# TC37XPD register map
Vendor: Infineon; Series: ATVMC; File version: 100
CPU: other r0p0, little endian, MPU, FPU, vendor SysTick, 4 interrupt priority bits
Registers are 32-bit, read-write, reset 0x0 unless marked. A register's access mark holds for its fields unless they carry their own. Offsets are from the block's base; [hi:lo] are bit positions; {n}, {i} and the like mark numbered series.

## QSPI0 — QSPI
Base 0xF0001C00
Same registers: QSPI1 0xF0001D00, QSPI2 0xF0001E00, QSPI3 0xF0001F00, QSPI4 0xF0002000
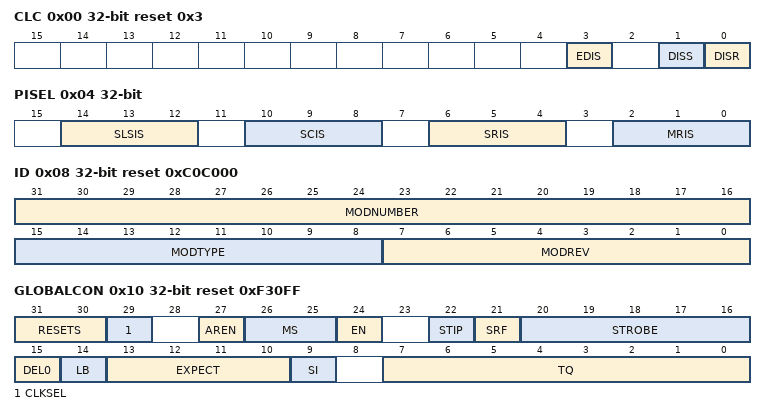
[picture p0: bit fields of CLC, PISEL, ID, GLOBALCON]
0x00 CLC access per field reset 0x3 — Clock Control Register resetvalue={Application Reset:0x3}
  [3] EDIS rw — Sleep Mode Enable Control EDIS. Used to enable the module 8217 s sleep mode.
  [1] DISS ro — Module Disable Status Bit DISS. Bit indicates the current status of the module.
  [0] DISR rw — Module Disable Request Bit DISR. Used for enable disable control of the module.
0x04 PISEL — Port Input Select Register resetvalue={Application Reset:0x0}
  [14:12] SLSIS — Slave Mode Slave Select Input Selection. The SLSIS must be programmed properly before the slave mode is set with GLOBALCON.MODE and the module is set to RUN mode. The following signal sources are available in this product if supported by the package
  [10:8] SCIS — Slave Mode Clock Input Select. SCIS selects one out of eight module kernel SCLK input lines that is used as clock input line in slave mode. Note that not all inputs are used in every device of the family. Selecting an unused input returns a continuous low value. The following signal sources are available in this product if supported by the package
  [6:4] SRIS — Slave Mode Receive Input Select. SRIS selects one out of eight MTSR receive input lines used in Slave Mode. Note that not all inputs are used in every device of the family. Selecting an unused input returns a continuous low value. The following signal sources are available in this product if supported by the package
  [2:0] MRIS — Master Mode Receive Input Select. MRIS selects one out of eight MRST receive input lines used in Master Mode. Note that not all inputs are used in every device of the family. Selecting an unused input returns a continuous low value. The following signal sources are available in this product if supported by the package
0x08 ID ro reset 0xC0C000 (reset mask 0xFFFFFF00) — Module Identification Register resetvalue={Application Reset:0x0C0C000}
  [31:16] MODNUMBER — Module Number Value MODNUMBER. This bit field together with MODTYPE uniquely identifies a module.
  [15:8] MODTYPE — Module Type MODTYPE. This bit field is C0 H . It defines a 32 bit module.
  [7:0] MODREV — Module Revision Number MODREV. MODREV defines the module revision number. The value of a module revision starts with 01 H first revision .
0x10 GLOBALCON access per field reset 0xF30FF — Global Configuration Register resetvalue={Application Reset:0x0F30FF}
  [31:30] RESETS wo — Bits for resetting sub modules per software RESETS. Write to this bit field triggers a reset operation. The reset operation cycle count depends on the Clock setup in the 2 Clock domains. The shortest time is 3 x T fast 3 x T slow. With the added margin the delay will be 10 times slowest clock between SPB and Kernel. The duration of reset operation depends on the used clock setups. It is 10 times of the slowest clock between SPB and Kernel. CLOCKSEL shall be enabled to use GLOBALCON.RESETS. After the Reset the CLOCKSEL will be also cleared in case of 10 11. For resetting the whole module kernel use alternatively the registers KRST0 xa0 xa0 KRST1 reset mechanism.
  [29] CLKSEL rw — Clock Select CLKSEL. Selects the clock source for the asynchronous block.
  [27] AREN rw — Automatic Reset Enable AREN. Enables the reset of the GLOBALCON .EN on baud rate and spike error in slave mode.
  [26:25] MS rw — Master Slave Mode MS. Selects if the module operates in master or slave mode. This bit field must be configured before the first write to the TXFIFO.
  [24] EN rw — Enable Bit EN. Used to request transition between PAUSE and RUN mode per software. Cleared by hardware automatically at leaving the following states disabled suspend and sleep. In order to determine if the requested state has actually been reached the STATUS .PHASE bit field should be polled. See also Operation Modes.
  [22] STIP rw — Slave Transmit Idle State Polarity STIP. This bit determines the logic level of the Slave Mode transmit signal MRST when the QSPI slave select input signals are inactive PISEL.SLSIS 160 185 160 000 B .
  [21] SRF rw — Stop on RxFIFO Full SRF. If this bit is set the data fetching out of the TxFIFO by the shift register stops when the RxFIFO is full in order to prevent RxFIFO overflow. Master mode only.
  [20:16] STROBE rw — Strobe Delay for SLSO0 in Delayed Mode STROBE. Defines the length of the SLSO0 delay in T Q time units as defined for channel z T Q units selected by the current BACON .CS if GLOBALCON .DEL0 160 160 1.
  [15] DEL0 rw — Delayed Mode for SLSO0 DEL0. Switches the delayed mode external slave select expansion mode on and off
  [14] LB rw — Loop Back Control LB. Selects if the transmit output is internally connected to the receive input for test purposes. For detailed description see the Loop Back Mode section.
  [13:10] EXPECT rw — Time Out Value for the Expect Phase EXPECT. expressed in T QSPI units
  [9] SI rw — Status Injection SI. Selects if the status register content injection into the RxFIFO is enabled or disabled. The status injections if enabled is performed after each data block depending on the BACON .DL and BYTE setting.
  [7:0] TQ rw — Global Time Quantum Length TQ. Common n divider scaling the baud rates of all channels in direction of higher or lower baud rates. Must not be changed during a running transaction.
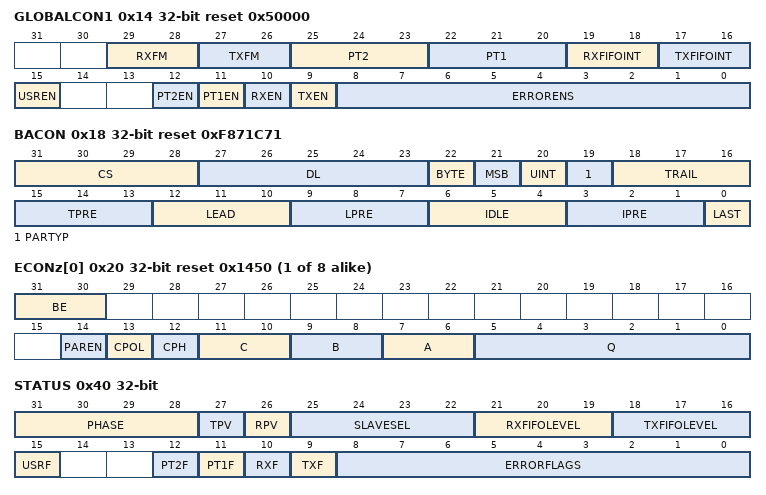
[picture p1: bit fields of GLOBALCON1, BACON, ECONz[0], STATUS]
0x14 GLOBALCON1 reset 0x50000 — Global Configuration Register 1 resetvalue={Application Reset:0x50000}
  [29:28] RXFM — RXFIFO Mode RXFM. Selects the RXFIFO mode.
  [27:26] TXFM — TXFIFO Mode TXFM. Selects the TXFIFO mode.
  [25:23] PT2 — Phase Transition Event 2 PT2. Selects the second phase transition to trigger the PT2 interrupt. In Master Mode the following events are available. In Slave Mode only the SLSI signal rising edge triggers the interrupt for PT2. For this purpose always use the setting 101 EOF . This interrupt is independent of the CS value.
  [22:20] PT1 — Phase Transition Event 1 PT1. Selects the first phase transition to trigger the PT interrupt.
  [19:18] RXFIFOINT — Receive FIFO Interrupt Threshold RXFIFOINT. In Combined Mode as long as the RXFIFO filling level is equal or greater than this threshold than each move of data or status if enabled into the RXFIFO triggers a receive interrupt. In Batch mode interrupt is generated only at the moment of filling level exceeding this threshold level. In Single Mode this bit field is don 8217 t care. Reset value of the level is 01 .
  [17:16] TXFIFOINT — Transmit FIFO Interrupt Threshold TXFIFOINT. In Combined Mode as long as the TXFIFO filling level is equal or less than this threshold than each move of data or configuration from the TXFIFO triggers a transmit interrupt. In Batch Mode interrupt is generated only at the moment of filling level falling below the threshold level. In Single Mode this bit field is don 8217 t care. Reset value of the level is 01 .
  [15] USREN — Interrupt on USR Event Enable USREN. Enables the USR interrupt on an USR event as selected by the PT1 bit field. In Move Counter mode of operation User Interrupt line is reused for the IAL and IBL interrupts which can be enabled by MCCON .IALEN and MCCON .IBLEN. Bit USREN does not influence these interrupts.
  [12] PT2EN — Interrupt on PT2 Event Enable PT2EN. Enables the PT interrupt on an PT2 event as selected by the PT2 bit field.
  [11] PT1EN — Interrupt on PT1 Event Enable PT1EN. Enables the PT interrupt on an PT1 event as selected by the PT1 bit field.
  [10] RXEN — RX Interrupt Event Enable RXEN. Enables the Rx interrupt.
  [9] TXEN — Tx Interrupt Event Enable TXEN. Enables the Tx interrupt.
  [8:0] ERRORENS — Error Enable Bits ERRORENS. Bits for enabling interrupt on all available error types
0x18 BACON ro reset 0xF871C71 — Basic Configuration Register resetvalue={Application Reset:0x0F871C71}
  [31:28] CS — Channel Select CS. Selects the channel to which the subsequent data entry belongs channel the SLSO signal to be activated and the corresponding ECON configuration extension This bit field selects one slave in a range of 0 to 15 by driving one SLSO signal out of 16 available. In case of an external demux mode this bit field appears on the lines SLS01 to SLSO4 as it is additionally inverted or not as defined in the SSOC register.
  [27:23] DL — Data Length DL. Defines the data length in bits or bytes of one data block depending on the setting of the bit field BYTE. For the maximum baud rate of 50 160 MBaud the minimum data length possible is four.
  [22] BYTE — Byte BYTE. Defines if data length is expressed in bits or bytes. In Slave Mode BYTE must be 0 .
  [21] MSB — Shift MSB or LSB First MSB. This bit sets the shift direction of the shift register. If the MSB option is set and the data is a block longer than 32 bits the block must be fed into the TXFIFO in reverse direction from the end of the block until its beginning.
  [20] UINT — User Interrupt at the PT1 Event in the Subsequent Frames UINT. This bit is an enable signal for the PT1 event routed to the User Interrupt Service Request. The interrupt signals are generated until disabled with the next BACON.
  [19] PARTYP — Parity Type PARTYP. Valid for both receive and transmit direction
  [18:16] TRAIL — Trailing Delay Length TRAIL. Defines the length of the trailing delay in T PER units pre scaled with TPRE
  [15:13] TPRE — Prescaler for the Trailing Delay TPRE. Length in T PER units
  [12:10] LEAD — Leading Delay Length LEAD. Defines the length of the leading delay in T PER units pre scaled with LPRE
  [9:7] LPRE — Prescaler for the Leading Delay LPRE. Length in T PER units
  [6:4] IDLE — Idle Delay Length IDLE. Defines the length of both idle delays IDLEA and IDLEB in T PER units pre scaled with IPRE
  [3:1] IPRE — Prescaler for the Idle Delay IPRE. Length in T PER units
  [0] LAST — Last Word in a Frame LAST. Defines if the following data word is last in the current frame or not
{0x20+4i} ECONz[{i}] (i=0..7) reset 0x1450 — Configuration Extension 0 resetvalue={Application Reset:0x1450}
  [31:30] BE — Permutate bytes to from Big Endian BE
  [14] PAREN — Enable Parity Check PAREN. This bit field enables both the parity generation in transmit and parity check in receive direction.
  [13] CPOL — Clock Polarity CPOL. Idle level of the shift clock signal at the SCLK pin
  [12] CPH — Clock Phase CPH. Delay of one half SCLK clock cycle.
  [11:10] C — Bit Segment 3 C. Length expressed in time quantums of ECONz.Q.
  [9:8] B — Bit Segment 2 B. Length expressed in time quantums of ECONz.Q.
  [7:6] A — Bit Segment 1 A. Length expressed in time quantums of ECONz.Q.
  [5:0] Q — Time Quantum Q. Defines the time quantum length used by A B and C to define the baud rate and duty cycle by. This prescaler cascades the prescaler GLOBALCON.TQ.
0x40 STATUS access per field — Status Register resetvalue={Application Reset:0x0}
  [31:28] PHASE ro — Flags the ongoing phase PHASE. Displays the current phase number. Relevant only in master mode. In slave mode this bit field indicates always 0. Not 0 means busy.
  [27] TPV ro — Transmitted Parity Value TPV. Displays the last transmitted parity bit if parity was enabled. Else 0.
  [26] RPV ro — Received Parity Value RPV. Displays the last received parity bit if parity was enabled. Else if the parity is disabled reads 0.
  [25:22] SLAVESEL ro — Currently Active Slave Select Flag SLAVESEL. Displays the currently active slave select.
  [21:19] RXFIFOLEVEL ro — RXFIFO Filling Level RXFIFOLEVEL. Shows how many entries in the RXFIFO are waiting for software to move them to RAM
  [18:16] TXFIFOLEVEL ro — TXFIFO Filling Level TXFIFOLEVEL. Shows how many entries in the TXFIFO are waiting for transmission
  [15] USRF rw — User Interrupt Request Flag USRF. Flags an occurrence of an USR event. Writing 1 sets the flag and triggers an interrupt if GLOBALCON1 .USREN 160 160 1. Writing 0 has no effect.
  [12] PT2F rw — Phase Transition 2 Flag PT2F. In master mode flags an occurrence of a PT2 event as selected with the GLOBALCON1 .PT2 and triggers an interrupt if GLOBALCON1 .PT2EN 160 160 1. In slave mode set by the SLSI deactivated event. Writing 1 sets the flag and triggers an error interrupt. Writing 0 has no effect.
  [11] PT1F rw — Phase Transition 1 Flag PT1F. Flags an occurrence of a PT1 event as selected with the GLOBALCON1 .PT1 and triggers an interrupt if GLOBALCON1 .PT1EN 160 160 1. Writing 1 sets the flag and triggers an error interrupt. Writing 0 has no effect.
  [10] RXF rw — Receive Interrupt Request Flag RXF. Flags an occurrence of a request to empty the RXFIFO which is generated when an element is written into the FIFO and the FIFO filling level is equal or greater than the set threshold level. Writing 1 sets the flag and triggers an interrupt if GLOBALCON1 .RXEN 160 160 1. Writing 0 has no effect.
  [9] TXF rw — Transmit Interrupt Request Flag TXF. Flags an occurrence of a request to feed the TXFIFO which is generated when an element is fetched from the FIFO and the FIFO filling level is equal or less than the set threshold level. Writing 1 sets the flag and triggers an interrupt if GLOBALCON1 .TXEN 160 160 1. Writing 0 has no effect.
  [8:0] ERRORFLAGS rw — Sticky Flags Signalling Errors ERRORFLAGS. Writing 1 sets the error Flag and triggers an error interrupt if enabled. Writing 0 has no effect.
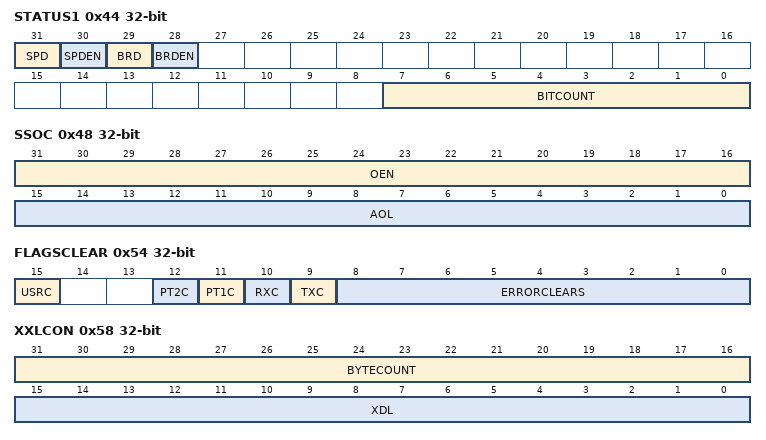
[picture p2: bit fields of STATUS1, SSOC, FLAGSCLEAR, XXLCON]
0x44 STATUS1 access per field — Status Register 1 resetvalue={Application Reset:0x0}
  [31] SPD rw — Spike Detection Flag SPD. Shows if spike has been detected. Write of 1 sets the bit and raises the event per software. Write of 0 has no effect.
  [30] SPDEN rw — Spike Detection Enable SPDEN. Enables the signal path.
  [29] BRD rw — Baud Rate Deviation Flag BRD. Shows if baud rate deviation has been detected. Write of 1 sets the bit and raises the event per software. Write of 0 has no effect.
  [28] BRDEN rw — Baud Rate Deviation Enable BRDEN. Enables the signal path.
  [7:0] BITCOUNT ro — Number of bits shifted out BITCOUNT. Supports up to 256 bits. A BITCOUNT value of greater than 0 indicates that a transmission is in progress. The value is not accurate it may be lower than the number of bits shifted. After transmission of the last bit BITCOUNT is set to zero.
0x48 SSOC — Slave Select Output Control Register resetvalue={Application Reset:0x0}
  [31:16] OEN — Enable Bits for the SLSO Outputs OEN. In disabled state the SLSO output drives the idle level as defined by the AOL bit field. 8220 0 8221 at certain position means that the corresponding SLSO is disabled. 8220 1 8221 means enabled.
  [15:0] AOL — Active Output Level for the SLSO Outputs AOL. The idle level is the inverted one. 8220 0 8221 at certain position means active low level for the corresponding SLSO. 8220 1 8221 means active high.
0x54 FLAGSCLEAR wo — Flags Clear Register resetvalue={Application Reset:0x0}
  [15] USRC — User Event Flag Clear USRC. Write of 1 clears the STATUS .USRF bit. Write of 0 has no effect. Read delivers 0.
  [12] PT2C — PT2 Event Flag Clear PT2C. Write of 1 clears the STATUS .PT2F bit. Write of 0 has no effect. Read delivers 0.
  [11] PT1C — PT1 Event Flag Clear PT1C. Write of 1 clears the STATUS .PT1F bit. Write of 0 has no effect. Read delivers 0.
  [10] RXC — Receive Event Flag Clear RXC. Write of 1 clears the STATUS .RXF bit. Write of 0 has no effect. Read delivers 0.
  [9] TXC — Transmit Event Flag Clear TXC. Write of 1 clears the STATUS .TXF bit. Write of 0 has no effect. Read delivers 0.
  [8:0] ERRORCLEARS — Write Only Bits for Clearing the Error Flags ERRORCLEARS. Writing 1 clears the corresponding error flag in the ERORRFLAGS bit field. Reading returns 0.
0x58 XXLCON access per field — Extra Large Data Configuration Register resetvalue={Application Reset:0x0}
  [31:16] BYTECOUNT ro — Extended Data Length BYTECOUNT. In the XXL mode shows the current state of the internal byte down counter bytes remaining to be sent . In short and long modes the value of this bit field is don 8217 t care.
  [15:0] XDL rw — Extended Data Length XDL. Defines the length of the data block in bytes in range of 2 to 65536. Overrides BACON .DL when BACON .BYTE 1 and BACON .DL 0.
0x5C MIXENTRY wo — MIX ENTRY Register resetvalue={Application Reset:0x0}
  [31:0] E — Entry Point to the TxFIFO E
0x60 BACONENTRY wo — BACON ENTRY Register resetvalue={Application Reset:0x0}
  [31:0] E — Entry Point to the TxFIFO E
{0x64+4i} DATAENTRYx[{i}] (i=0..7) wo — DATA ENTRY Register 0 resetvalue={Application Reset:0x0}
  [31:0] E — Entry Point to the TxFIFO E
0x90 RXEXIT ro — RX EXIT Register resetvalue={Application Reset:0x0}
  [31:0] E — Read Point from the RxFIFO E
0x94 RXEXITD ro — RX EXIT Debug Register resetvalue={Application Reset:0x0}
  [31:0] E — Read Point from the RxFIFO E
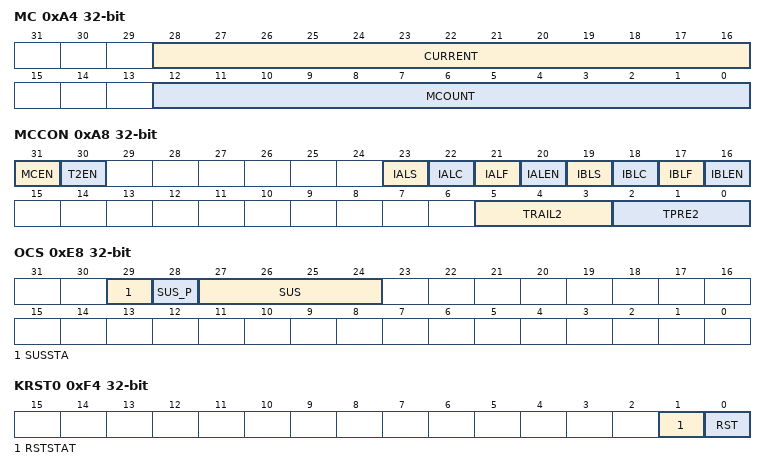
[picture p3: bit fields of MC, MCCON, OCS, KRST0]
0xA4 MC access per field — Move Counter Register resetvalue={Application Reset:0x0}
  [28:16] CURRENT ro — Current Status of the Move Counter CURRENT. Shows the current status of the Move Counter that is how many data blocks are to be transmitted until the end of the frame.
  [12:0] MCOUNT rw — Move Count MCOUNT. Defines the number of moves to be performed in short mode in range of 1 to 8191.
0xA8 MCCON access per field — Move Counter control Register resetvalue={Application Reset:0x0}
  [31] MCEN rw — Move Counter Enable MCEN. Enables the Move Counter feature. If enabled the MCOUNT value is taken in consideration otherwise the standard continuous mode is active.
  [30] T2EN rw — TRAIL 2 Injection Enable T2EN. This bit has to be configured before the transmission of the frame starts. If set a new value for the last trailing delay will be injected for the last data block as defined with the bit field TRAIL2. If not set the TRAIL value from the latest BACON will be valid also as the last trailing delay.
  [23] IALS wo — Set Bit for IALF IALS. Writing 1 sets the IALF and triggers an interrupt if enabled . Writing 0 has no effect. Returns 0 on read.
  [22] IALC wo — Clear Bit for IALF IALC. Writing 1 clears the IALF. Writing 0 has no effect. Returns 0 on read.
  [21] IALF ro — Interrupt After Last Flag IALF. Flag bit for this event.
  [20] IALEN rw — Interrupt After Last Enable IALEN. Enable bit for this event.
  [19] IBLS wo — Set Bit for IBLF IBLS. Writing 1 sets the IBLF and triggers an interrupt if enabled . Writing 0 has no effect. Returns 0 on read.
  [18] IBLC wo — Clear Bit for IBLF IBLC. Writing 1 clears the IBLF. Writing 0 has no effect. Returns 0 on read.
  [17] IBLF ro — Interrupt Before Last Flag IBLF. Flag bit for this event.
  [16] IBLEN rw — Interrupt Before Last Enable IBLEN. Enable bit for this event.
  [5:3] TRAIL2 rw — Last Trailing Delay TRAIL2. Trailing delay injected in the configuration register for the last data if T2EN is set. Defines the length of the leading delay in T PER units pre scaled with TPRE
  [2:0] TPRE2 rw — Prescaler for the Trailing Delay 2 TPRE2. Trailing delay injected in the configuration register for the last data if T2EN is set. Length in units T PER
0xE8 OCS access per field — OCDS Control and Status resetvalue={Debug Reset:0x0}
  [29] SUSSTA ro — Suspend State SUSSTA
  [28] SUS_P wo — SUS Write Protection SUS P. SUS is only written when SUS P is 1 otherwise unchanged. Read as 0.
  [27:24] SUS rw — OCDS Suspend Control SUS. Controls the sensitivity to the suspend signal coming from the OCDS Trigger Switch OTGS
0xEC KRSTCLR wo — Kernel Reset Status Clear Register resetvalue={Application Reset:0x0}
  [0] CLR — Kernel Reset Status Clear CLR. Read always as 0.
0xF0 KRST1 — Kernel Reset Register 1 resetvalue={Application Reset:0x0}
  [0] RST — Kernel Reset RST. This reset bit can be used to request for a kernel reset. The kernel reset will be executed if the reset bits of both kernel reset registers is set. The RST bit will be cleared re set to 180 0 180 by the BPI FPI after the kernel reset was executed.
0xF4 KRST0 access per field — Kernel Reset Register 0 resetvalue={Application Reset:0x0}
  [1] RSTSTAT ro — Kernel Reset Status RSTSTAT. This bit indicates wether a kernel reset was executed or not. This bit is set by the BPI FPI after the execution of a kernel reset in the same clock cycle both reset bits. This bit can be cleared by writing with 180 1 180 to the CLR bit in the related KRSTCLR register.
  [0] RST rw — Kernel Reset RST. This reset bit can be used to request for a kernel reset. The kernel reset will be executed if the reset bits of both kernel registers are set. The RST bit will be cleared re set to 180 0 180 by the BPI FPI after the kernel reset was executed.
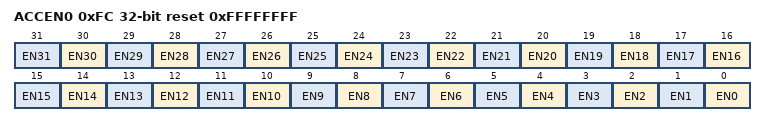
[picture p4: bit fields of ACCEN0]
0xFC ACCEN0 reset 0xFFFFFFFF — Access Enable Register 0 resetvalue={Application Reset:0x0FFFFFFFF}
  [n] EN{n} (n=0..31) — Access Enable for Master TAG ID 31 EN31. This bit enables write access to the module kernel addresses for transactions with the Master TAG ID n
